AUTOSAR XML (schema 3.0.2)
package /pk_Tick
  mode declaration group mdg_Tick: initial-mode=md_Init
    mode md_Init
    mode md_Run
  sender receiver interface in_Tick_tick
    data count: sw-calibration-access=READ-ONLY, type=dt_xtUMLInteger
  client server interface in_TickReset_resetOp
    operation op_resetOp
      arg count: sw-calibration-access=READ-ONLY, type=dt_xtUMLInteger, direction=IN
  sender receiver interface modeIfc
    mode declaration group prototype mdgp_Tick: type=mdg_Tick
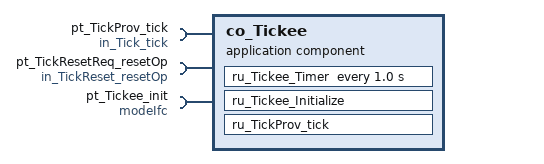
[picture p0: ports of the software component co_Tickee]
  application software component type co_Tickee
    require port pt_TickProv_tick: required-interface=in_Tick_tick
    require port pt_TickResetReq_resetOp: required-interface=in_TickReset_resetOp
    require port pt_Tickee_init: required-interface=modeIfc
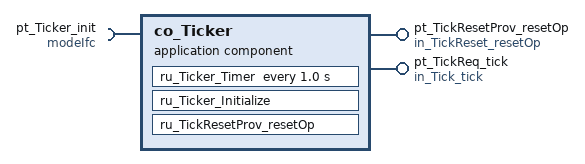
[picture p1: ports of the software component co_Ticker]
  application software component type co_Ticker
    provide port pt_TickResetProv_resetOp: provided-interface=in_TickReset_resetOp
    provide port pt_TickReq_tick: provided-interface=in_Tick_tick
    require port pt_Ticker_init: required-interface=modeIfc
  composition type cz_Tickee
    require port pt_TickProv_tick: required-interface=in_Tick_tick
    require port pt_TickResetReq_resetOp: required-interface=in_TickReset_resetOp
    component cp_Tickee: type=co_Tickee
    delegate cp_Tickee.pt_TickProv_tick <-> outer port cz_Tickee/pt_TickProv_tick
    delegate cp_Tickee.pt_TickResetReq_resetOp <-> outer port cz_Tickee/pt_TickResetReq_resetOp
  composition type cz_Ticker
    provide port pt_TickResetProv_resetOp: provided-interface=in_TickReset_resetOp
    provide port pt_TickReq_tick: provided-interface=in_Tick_tick
    component cp_Ticker: type=co_Ticker
    delegate cp_Ticker.pt_TickResetProv_resetOp <-> outer port cz_Ticker/pt_TickResetProv_resetOp
    delegate cp_Ticker.pt_TickReq_tick <-> outer port cz_Ticker/pt_TickReq_tick
  composition type cz_default
    component cp_cz_Tickee: type=cz_Tickee
    component cp_cz_Ticker: type=cz_Ticker
    connect cp_cz_Ticker.pt_TickReq_tick -> cp_cz_Tickee.pt_TickProv_tick
    connect cp_cz_Ticker.pt_TickResetProv_resetOp -> cp_cz_Tickee.pt_TickResetReq_resetOp
  internal behavior ib_Tickee: component=co_Tickee, supports-multiple-instantiation=true
    timing event ev_Tickee_Timer: start-on-event=ru_Tickee_Timer, period=1.0
    mode switch event ev_Tickee_Initialize: start-on-event=ru_Tickee_Initialize, activation=ENTRY, mode=pt_Tickee_init.mdgp_Tick.md_Init
    data received event ev_TickProv_tick: start-on-event=ru_TickProv_tick, data=pt_TickProv_tick.count
    exclusive area ea_Tickee
    runnable ru_Tickee_Timer: can-be-invoked-concurrently=true, can-enter-exclusive-area=ea_Tickee, symbol=ib_Tickee_ru_TickeeTimer
      sync call TickResetReq_resetOp: operation=pt_TickResetReq_resetOp.op_resetOp, timeout=0.5
    runnable ru_Tickee_Initialize: can-be-invoked-concurrently=true, can-enter-exclusive-area=ea_Tickee, symbol=ib_Tickee_ru_Tickee_Initialize
    runnable ru_TickProv_tick: can-be-invoked-concurrently=true, can-enter-exclusive-area=ea_Tickee, symbol=ib_Tickee_ru_TickProv_count
      data receive point TickProv_tick: data-element=pt_TickProv_tick.count
      sync call TickResetReq_resetOp: operation=pt_TickResetReq_resetOp.op_resetOp, timeout=0.5
  internal behavior ib_Ticker: component=co_Ticker, supports-multiple-instantiation=true
    timing event ev_Ticker_Timer: start-on-event=ru_Ticker_Timer, period=1.0
    mode switch event ev_Ticker_Initialize: start-on-event=ru_Ticker_Initialize, activation=ENTRY, mode=pt_Ticker_init.mdgp_Tick.md_Init
    operation invoked event ev_TickResetProv_resetOp: start-on-event=ru_TickResetProv_resetOp, operation=pt_TickResetProv_resetOp.op_resetOp
    exclusive area ea_Ticker
    runnable ru_Ticker_Timer: can-be-invoked-concurrently=true, can-enter-exclusive-area=ea_Ticker, symbol=ib_Ticker_ru_TickerTimer
      data send point TickReq_tick: data-element=pt_TickReq_tick.count
    runnable ru_Ticker_Initialize: can-be-invoked-concurrently=true, can-enter-exclusive-area=ea_Ticker, symbol=ib_Ticker_ru_Ticker_Initialize
      data send point TickReq_tick: data-element=pt_TickReq_tick.count
    runnable ru_TickResetProv_resetOp: can-be-invoked-concurrently=true, can-enter-exclusive-area=ea_Ticker, symbol=ib_Ticker_ru_TickResetProv_resetOp
      data send point TickReq_tick: data-element=pt_TickReq_tick.count
  swc implementation im_Tickee: code-generator=BridgePoint xtUML MC3020, programming-language=C, behavior=ib_Tickee
  swc implementation im_Ticker: code-generator=BridgePoint xtUML MC3020, programming-language=C, behavior=ib_Ticker
